# CY8C5868AXI_LP035 register map
File version: 0.1
CY8C58LP
Registers are 8-bit, read-write, no defined reset value unless marked. A register's access mark holds for its fields unless they carry their own. Offsets are from the block's base; lines under a group give offsets from that group; [hi:lo] are bit positions; {n}, {i} and the like mark numbered series; 'fields as' and 'values as' point back to an identical list; <NAME> marks a mode.

## Memory map
0x40006404 I2C_M size 0x81

## I2C_M
Base 0x40006404
0x00 I2C_M_UDB_MSTR_DATA — Data
  [7:0] data — This register provides read/write access to the Shift register.
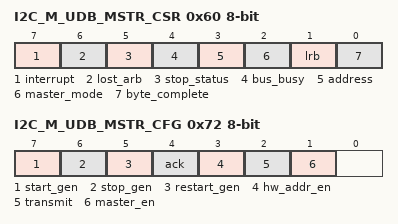
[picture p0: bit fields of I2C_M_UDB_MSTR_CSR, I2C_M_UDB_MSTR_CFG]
0x60 I2C_M_UDB_MSTR_CSR — Status Register
  [7] interrupt ro — Interrupt bit
  [6] lost_arb ro
  [5] stop_status
  [4] bus_busy ro
  [3] address ro
  [2] master_mode ro
  [1] lrb ro
  [0] byte_complete ro
0x72 I2C_M_UDB_MSTR_CFG — Configuration Register
  [7] start_gen, [6] stop_gen, [5] restart_gen, [4] ack, [3] hw_addr_en, [2] transmit, [1] master_en
0x80 I2C_M_UDB_MSTR_INT_MASK — Interrupt Mask
